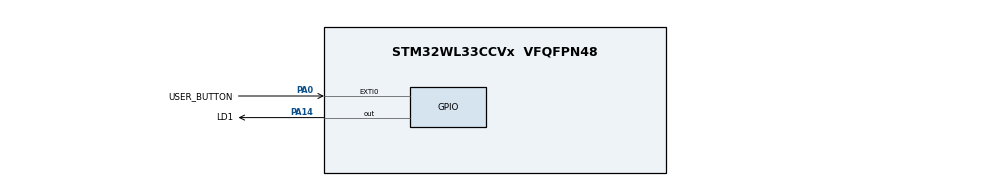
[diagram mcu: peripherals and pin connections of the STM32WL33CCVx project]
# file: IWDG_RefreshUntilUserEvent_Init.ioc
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IWDG.Prescaler=IWDG_PRESCALER_4
IWDG.Reload=4095
IWDG.Window=4095
Mcu.Family=STM32WL3
Mcu.Name=STM32WL33CCVx
Mcu.Package=VFQFPN48
NVIC.GPIOA_IRQn=true\:0\:0\:false\:false\:true\:true\:true\:true
OSCIN.Mode=HSE-External-Oscillator
OSCIN.Signal=RCC_OSC_IN
OSCOUT.Mode=HSE-External-Oscillator
OSCOUT.Signal=RCC_OSC_OUT
PA0.GPIO_Label=USER_BUTTON
PA0.GPIO_ModeDefaultEXTI=GPIO_MODE_IT_FALLING
PA0.GPIO_PuPd=GPIO_PULLUP
PA0.Signal=GPXTI0
PA14.GPIO_Label=LD1
PA14.GPIO_ModeDefaultOutputPP=GPIO_MODE_OUTPUT_PP
PA14.GPIO_Speed=GPIO_SPEED_FREQ_VERY_HIGH
PA14.Signal=GPIO_Output
ProjectManager.HeapSize=0x000
ProjectManager.StackSize=0xC00
ProjectManager.TargetToolchain=EWARM V9.30
RCC.HSE_VALUE=48000000
RCC.HSI_VALUE=64000000
RCC.LSE_VALUE=32768
RCC.RC64MPLLSource=RCC_LSCOSOURCE_PLL64
VP_IWDG_VS_IWDG.Mode=IWDG_Activate
VP_PWR_VS_SECSignals.Mode=Security/Privilege
board=custom

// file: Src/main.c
/* USER CODE BEGIN Header */
/**
  ******************************************************************************
  * @file    Examples_LL/IWDG/IWDG_RefreshUntilUserEvent_Init/Src/main.c
  * @author  MCD Application Team
  * @brief   This example describes how to configure IWDG down-counter (without Window)
  *          using the STM32WL3x IWDG LL API.
  *          Peripheral initialization done using LL unitary services functions.
  ******************************************************************************
  * @attention
  *
  * Copyright (c) 2024 STMicroelectronics.
  * All rights reserved.
  *
  * This software is licensed under terms that can be found in the LICENSE file
  * in the root directory of this software component.
  * If no LICENSE file comes with this software, it is provided AS-IS.
  *
  ******************************************************************************
  */
/* USER CODE END Header */
#include "main.h"

/* USER CODE BEGIN PV */
static __IO uint8_t ubKeyPressed = 0;
/* USER CODE END PV */

void SystemClock_Config(void);
void PeriphCommonClock_Config(void);
static void MX_GPIO_Init(void);
static void MX_IWDG_Init(void);
/* USER CODE BEGIN PFP */
void     Check_IWDG_Reset(void);
void     LED_On(void);
/* USER CODE END PFP */

int main(void)
{

  /* USER CODE BEGIN 1 */
  LL_APB0_GRP1_EnableClock(LL_APB0_GRP1_PERIPH_WDG);
  /* USER CODE END 1 */

  /* MCU Configuration--------------------------------------------------------*/

  /* Reset of all peripherals, Initializes the Flash interface and the Systick. */
  LL_APB0_GRP1_EnableClock(LL_APB0_GRP1_PERIPH_SYSCFG);

  /* Configure the system clock */
  SystemClock_Config();

  /* Configure the peripherals common clocks */
  PeriphCommonClock_Config();

  /* USER CODE BEGIN SysInit */

  /* Check if the system has resumed from IWDG reset */
  Check_IWDG_Reset();

  /* USER CODE END SysInit */

  /* Initialize all configured peripherals */
  MX_GPIO_Init();
  MX_IWDG_Init();

  /* Infinite loop */
  while (1)
  {

    /* USER CODE BEGIN 3 */

    if (1 != ubKeyPressed)
    {
      /* Refresh IWDG down-counter to default value */
      LL_IWDG_ReloadCounter(IWDG);

      LL_GPIO_TogglePin(LD1_GPIO_Port, LD1_Pin);
      /* Note that period used for Counter Reload MUST be higher than blinking timing value*/
      /* This Counter reload timeout period is a function of this value and the
         clock prescaler. Refer to the datasheet for the timeout information  */
      LL_mDelay(LED_BLINK_FAST);
    }
  }

  /* USER CODE END 3 */
}

void SystemClock_Config(void)
{
  LL_RCC_LSI_Enable();

   /* Wait till LSI is ready */
  while(LL_RCC_LSI_IsReady() != 1)
  {
  }

   /* Set HSE Capacitor Tuning */
  LL_RCC_HSE_SetCapacitorTuning(CFG_HW_RCC_HSE_CAPACITOR_TUNE);

   /* Set HSE startup Current */
 LL_RCC_HSE_SetStartupCurrent(0);

   /* Set HSE Amplitude Threshold */
 LL_RCC_HSE_SetAmplitudeThreshold(0);

   /* Set HSE Current Control */
  LL_RCC_HSE_SetCurrentControl(40);

   /* Enable the HSE */
  LL_RCC_HSE_Enable();

   /* Wait till HSE is ready */
  while(LL_RCC_HSE_IsReady() != 1)
  {
  }

  LL_FLASH_SetLatency(LL_FLASH_WAIT_STATES_1);

   /* Enable the RC64MPLL*/
  LL_RCC_RC64MPLL_Enable();

   /* Wait till RC64MPLL is ready */
  while(LL_RCC_RC64MPLL_IsReady() != 1)
  {
  }

  LL_RCC_SetRC64MPLLPrescaler(LL_RCC_RC64MPLL_DIV_1);

   /* Update the SystemCoreClock global variable */
  LL_SetSystemCoreClock(64000000);

   /* Configure the source of time base considering new system clocks settings*/
  LL_Init1msTick(64000000);
}

void PeriphCommonClock_Config(void)
{
  LL_RCC_SetSMPSPrescaler(LL_RCC_SMPS_DIV_2);

   /* Enable the KRM*/
  LL_RCC_KRM_Enable();
  LL_RCC_KRM_SetRateMultiplier(2);
}

static void MX_IWDG_Init(void)
{

  LL_RCC_LSCO_SetSource(LL_RCC_LSCO_CLKSOURCE_LSI);

  LL_IWDG_Enable(IWDG);
  LL_IWDG_EnableWriteAccess(IWDG);
  LL_IWDG_SetPrescaler(IWDG, LL_IWDG_PRESCALER_4);
  LL_IWDG_SetReloadCounter(IWDG, 4095);
  while (LL_IWDG_IsReady(IWDG) != 1)
  {
  }

  LL_IWDG_ReloadCounter(IWDG);

}

static void MX_GPIO_Init(void)
{
  LL_GPIO_InitTypeDef GPIO_InitStruct = {0};

  /* GPIO Ports Clock Enable */
  LL_AHB1_GRP1_EnableClock(LL_AHB1_GRP1_PERIPH_GPIOA);

  /**/
  LL_GPIO_ResetOutputPin(LD1_GPIO_Port, LD1_Pin);

  /**/
  LL_GPIO_SetPinPull(USER_BUTTON_GPIO_Port, USER_BUTTON_Pin, LL_GPIO_PULL_UP);

  /**/
  LL_EXTI_EnableIT(LL_EXTI_LINE_PA0);

  /**/
  LL_GPIO_SetPinMode(USER_BUTTON_GPIO_Port, USER_BUTTON_Pin, LL_GPIO_MODE_INPUT);

  /**/
  GPIO_InitStruct.Pin = LD1_Pin;
  GPIO_InitStruct.Mode = LL_GPIO_MODE_OUTPUT;
  GPIO_InitStruct.Speed = LL_GPIO_SPEED_FREQ_VERY_HIGH;
  GPIO_InitStruct.OutputType = LL_GPIO_OUTPUT_PUSHPULL;
  GPIO_InitStruct.Pull = LL_GPIO_PULL_NO;
  LL_GPIO_Init(LD1_GPIO_Port, &GPIO_InitStruct);

  /* EXTI interrupt init*/
  NVIC_SetPriority(GPIOA_IRQn, 0);
  NVIC_EnableIRQ(GPIOA_IRQn);

  /* USER CODE BEGIN MX_GPIO_Init_2 */
  LL_EXTI_EnableIT(LL_EXTI_LINE_PA0);
  LL_GPIO_SetOutputPin(LD1_GPIO_Port, LD1_Pin);
  /* USER CODE END MX_GPIO_Init_2 */
}

/* USER CODE BEGIN 4 */

/**
  * @brief  This function check if the system has resumed from IWDG reset
  * @param  None
  * @retval None
  */
void Check_IWDG_Reset(void)
{
  if ((RAM_VR.ResetReason & RCC_CSR_WDGRSTF) == RCC_CSR_WDGRSTF)
  {
    /* clear IWDG reset flag */
    LL_RCC_ClearResetFlags();

    /* Re-Initialize GPIO configured peripheral */
    MX_GPIO_Init();

    /* turn Led on and wait for user event to perform example again */
    LED_On();

    while(ubKeyPressed != 1)
    {
    }

    /* Reset ubKeyPressed value */
    ubKeyPressed = 0;
  }
}

/**
  * @brief  Turn-on LD1.
  * @param  None
  * @retval None
  */
void LED_On(void)
{
  /* Turn LD1 on */
  LL_GPIO_ResetOutputPin(LD1_GPIO_Port, LD1_Pin);
}

/******************************************************************************/
/*   USER IRQ HANDLER TREATMENT                                               */
/******************************************************************************/
/**
  * @brief  Function to manage IRQ Handler
  * @param  None
  * @retval None
  */
void UserButton_Callback(void)
{
  ubKeyPressed = 1;
}

/* USER CODE END 4 */

void Error_Handler(void)
{
}
